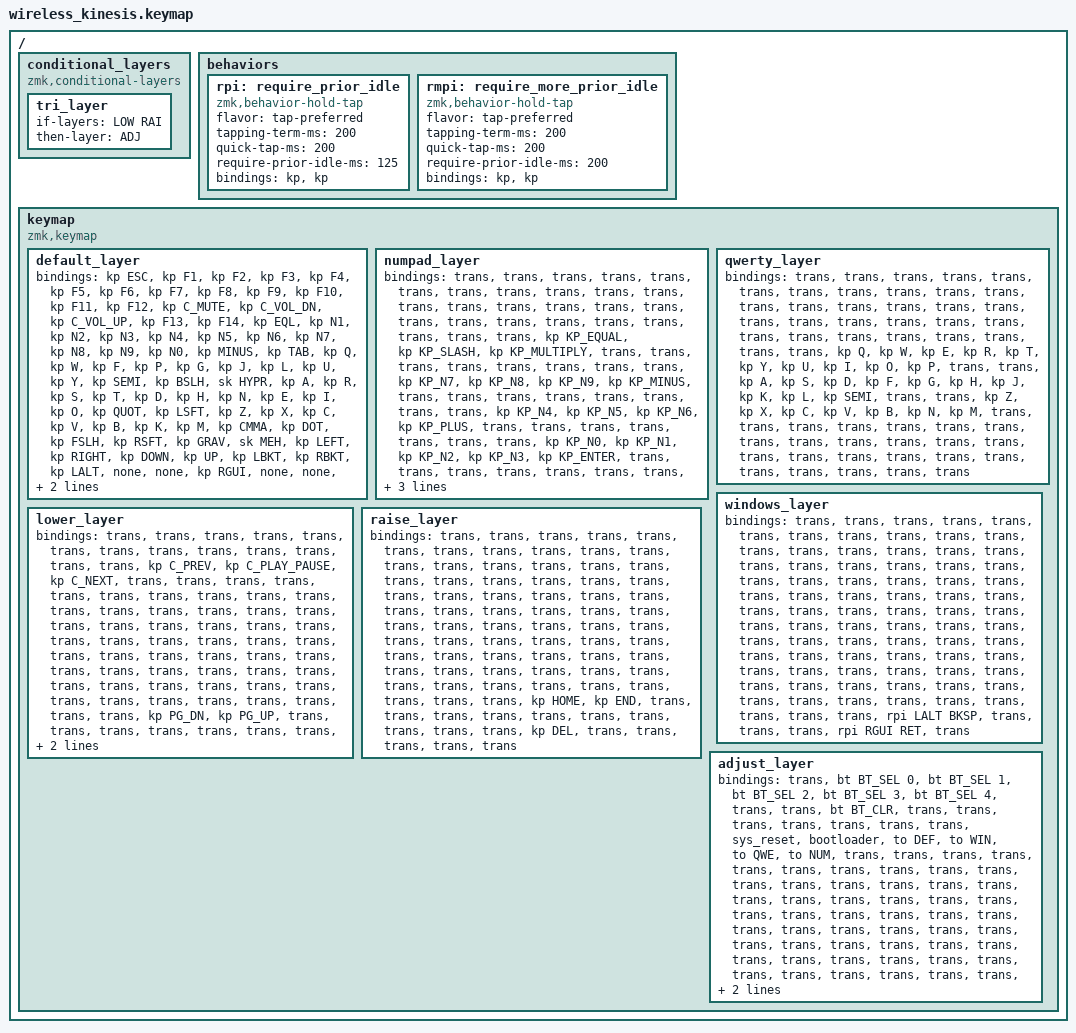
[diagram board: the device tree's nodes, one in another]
#include <behaviors.dtsi>
#include <dt-bindings/zmk/keys.h>
#include <dt-bindings/zmk/bt.h>

// Layers defines
#define DEF   0
#define NUM   1
#define QWE   2
#define WIN   3
#define LOW   4
#define RAI   5
#define ADJ   6

#define HYPR LS(LC(LA(LGUI)))
#define MEH  LS(LC(LALT))

/ {
    conditional_layers {
        compatible = "zmk,conditional-layers";
        tri_layer {
            if-layers = <LOW RAI>;
            then-layer = <ADJ>;
        };
    };

    behaviors {
        rpi: require_prior_idle {
            compatible = "zmk,behavior-hold-tap";
            #binding-cells = <2>;
            flavor = "tap-preferred";
            tapping-term-ms = <200>;
            quick-tap-ms = <200>;
            require-prior-idle-ms = <125>;
            bindings = <&kp>, <&kp>;
        };
        // This is only used for the `SPACE` mod-tap, I had some false positives on it.
        // Since space is fired pretty quickly during fast typing, increasing the `require_prior_idle`
        // value from `125` to `200` will make it less likely to trigger false positives.
        // See https://zmk.dev/docs/behaviors/hold-tap#advanced-configuration
        rmpi: require_more_prior_idle {
            compatible = "zmk,behavior-hold-tap";
            #binding-cells = <2>;
            flavor = "tap-preferred";
            tapping-term-ms = <200>;
            quick-tap-ms = <200>;
            require-prior-idle-ms = <200>;
            bindings = <&kp>, <&kp>;
        };
    };

    keymap {
        compatible = "zmk,keymap";

        default_layer { // 0
            bindings = <
&kp ESC   &kp F1 &kp F2 &kp F3 &kp F4 &kp F5 &kp F6 &kp F7 &kp F8                    &kp F9 &kp F10 &kp F11 &kp F12 &kp C_MUTE &kp C_VOL_DN &kp C_VOL_UP &kp F13 &kp F14

&kp EQL   &kp N1   &kp N2  &kp N3   &kp N4    &kp N5                                                  &kp N6  &kp N7   &kp N8   &kp N9   &kp N0   &kp MINUS
&kp TAB   &kp Q    &kp W   &kp F    &kp P     &kp G                                                   &kp J   &kp L    &kp U    &kp Y    &kp SEMI &kp BSLH
&sk HYPR  &kp A    &kp R   &kp S    &kp T     &kp D                                                   &kp H   &kp N    &kp E    &kp I    &kp O    &kp QUOT
&kp LSFT  &kp Z    &kp X   &kp C    &kp V     &kp B                                                   &kp K   &kp M    &kp CMMA &kp DOT  &kp FSLH &kp RSFT
          &kp GRAV &sk MEH &kp LEFT &kp RIGHT                                                                 &kp DOWN &kp UP   &kp LBKT &kp RBKT

                                                          &kp LALT &none              &none   &kp RGUI
                                                                   &none              &none
                                     &rpi LGUI BKSP  &mt LCTL ESC  &sl LOW            &sl RAI &rpi RALT RET &rmpi RCTL SPC
            >;
        };

        numpad_layer { // 1
            bindings = <
&trans    &trans &trans &trans &trans &trans &trans &trans &trans                    &trans &trans  &trans  &trans  &trans  &trans  &trans  &trans  &trans 

&trans    &trans   &trans  &trans   &trans    &trans                                                  &trans  &trans   &kp KP_EQUAL &kp KP_SLASH &kp KP_MULTIPLY    &trans 
&trans    &trans   &trans  &trans   &trans    &trans                                                  &trans  &kp KP_N7   &kp KP_N8    &kp KP_N9    &kp KP_MINUS  &trans  
&trans    &trans   &trans  &trans   &trans    &trans                                                  &trans  &kp KP_N4   &kp KP_N5    &kp KP_N6    &kp KP_PLUS  &trans  
&trans    &trans   &trans  &trans   &trans    &trans                                                  &kp KP_N0 &kp KP_N1   &kp KP_N2    &kp KP_N3    &kp KP_ENTER &trans  
          &trans   &trans  &trans   &trans                                                                    &trans   &trans    &kp KP_DOT   &kp KP_ENTER

                                                    &trans        &trans             &trans   &trans  
                                                                  &trans             &trans   
                                            &trans   &trans       &trans             &trans   &trans  &trans 
            >;
        };

        qwerty_layer { // 2
            bindings = <
&trans    &trans &trans &trans &trans &trans &trans &trans &trans                    &trans &trans  &trans  &trans  &trans  &trans  &trans  &trans  &trans 

&trans    &trans   &trans  &trans   &trans    &trans                                                  &trans  &trans   &trans   &trans   &trans   &trans 
&trans    &kp Q    &kp W   &kp E    &kp R     &kp T                                                   &kp Y   &kp U    &kp I    &kp O    &kp P    &trans  
&trans    &kp A    &kp S   &kp D    &kp F     &kp G                                                   &kp H   &kp J    &kp K    &kp L    &kp SEMI &trans  
&trans    &kp Z    &kp X   &kp C    &kp V     &kp B                                                   &kp N   &kp M    &trans   &trans   &trans   &trans  
          &trans   &trans  &trans   &trans                                                                    &trans   &trans   &trans   &trans  

                                                    &trans        &trans             &trans   &trans  
                                                                  &trans             &trans   
                                            &trans   &trans       &trans             &trans   &trans  &trans 
            >;
        };

        windows_layer { // 3
            bindings = <
&trans    &trans &trans &trans &trans &trans &trans &trans &trans                    &trans &trans  &trans  &trans  &trans  &trans  &trans  &trans  &trans 

&trans    &trans   &trans  &trans   &trans    &trans                                                  &trans  &trans   &trans   &trans   &trans   &trans 
&trans    &trans   &trans  &trans   &trans    &trans                                                  &trans  &trans   &trans   &trans   &trans   &trans  
&trans    &trans   &trans  &trans   &trans    &trans                                                  &trans  &trans   &trans   &trans   &trans   &trans  
&trans    &trans   &trans  &trans   &trans    &trans                                                  &trans  &trans   &trans   &trans   &trans   &trans  
          &trans   &trans  &trans   &trans                                                                    &trans   &trans   &trans   &trans  

                                                    &trans        &trans             &trans   &trans  
                                                                  &trans             &trans   
                                            &rpi LALT BKSP &trans       &trans             &trans   &rpi RGUI RET  &trans 
            >;
        };

        lower_layer { // 4
            bindings = <
&trans    &trans &trans &trans &trans &trans &trans &trans &trans                    &trans &trans &trans &trans &kp C_PREV &kp C_PLAY_PAUSE &kp C_NEXT &trans  &trans 

&trans    &trans   &trans  &trans   &trans    &trans                                                  &trans  &trans    &trans    &trans   &trans   &trans 
&trans    &trans   &trans  &trans   &trans    &trans                                                  &trans  &trans    &trans    &trans   &trans   &trans  
&trans    &trans   &trans  &trans   &trans    &trans                                                  &trans  &trans    &trans    &trans   &trans   &trans  
&trans    &trans   &trans  &trans   &trans    &trans                                                  &trans  &trans    &trans    &trans   &trans   &trans  
          &trans   &trans  &trans   &trans                                                                    &kp PG_DN &kp PG_UP &trans   &trans  

                                                    &trans        &trans             &trans   &trans  
                                                                  &trans             &trans   
                                            &trans   &trans       &trans             &trans   &trans  &trans 
    >;
        };

        raise_layer { // 5
            bindings = <
&trans    &trans &trans &trans &trans &trans &trans &trans &trans                    &trans &trans  &trans  &trans  &trans  &trans  &trans  &trans  &trans 

&trans    &trans   &trans  &trans   &trans    &trans                                                  &trans  &trans   &trans   &trans   &trans   &trans 
&trans    &trans   &trans  &trans   &trans    &trans                                                  &trans  &trans   &trans   &trans   &trans   &trans  
&trans    &trans   &trans  &trans   &trans    &trans                                                  &trans  &trans   &trans   &trans   &trans   &trans  
&trans    &trans   &trans  &trans   &trans    &trans                                                  &trans  &trans   &trans   &trans   &trans   &trans  
          &trans   &trans  &kp HOME &kp END                                                                   &trans   &trans   &trans   &trans  

                                                    &trans        &trans             &trans   &trans  
                                                                  &trans             &trans   
                                            &kp DEL  &trans       &trans             &trans   &trans  &trans 
            >;
        };

        adjust_layer { //6
            bindings = <
&trans     &bt BT_SEL 0 &bt BT_SEL 1 &bt BT_SEL 2 &bt BT_SEL 3 &bt BT_SEL 4 &trans &trans &bt BT_CLR                &trans &trans  &trans  &trans  &trans  &trans  &trans  &sys_reset  &bootloader

&to  DEF  &to  WIN &to  QWE &to  NUM &trans    &trans                                                                      &trans  &trans   &trans   &trans   &trans   &trans 
&trans    &trans   &trans   &trans   &trans    &trans                                                                      &trans  &trans   &trans   &trans   &trans   &trans  
&trans    &trans   &trans   &trans   &trans    &trans                                                                      &trans  &trans   &trans   &trans   &trans   &trans  
&trans    &trans   &trans   &trans   &trans    &trans                                                                      &trans  &trans   &trans   &trans   &trans   &trans  
          &trans   &trans   &trans   &trans                                                                                        &trans   &trans   &trans   &trans  

                                                     &trans        &trans                                 &trans   &trans  
                                                                   &trans                                 &trans   
                                             &trans   &trans       &trans                                 &trans   &trans  &trans 
            >;
        };

    };
};

/*
 * Template:
 ```c
&trans    &trans &trans &trans &trans &trans &trans &trans &trans                    &trans &trans  &trans  &trans  &trans  &trans  &trans  &trans  &trans 

&trans    &trans   &trans  &trans   &trans    &trans                                                  &trans  &trans   &trans   &trans   &trans   &trans 
&trans    &trans   &trans  &trans   &trans    &trans                                                  &trans  &trans   &trans   &trans   &trans   &trans  
&trans    &trans   &trans  &trans   &trans    &trans                                                  &trans  &trans   &trans   &trans   &trans   &trans  
&trans    &trans   &trans  &trans   &trans    &trans                                                  &trans  &trans   &trans   &trans   &trans   &trans  
          &trans   &trans  &trans   &trans                                                                    &trans   &trans   &trans   &trans  

                                                    &trans        &trans             &trans   &trans  
                                                                  &trans             &trans   
                                            &trans   &trans       &trans             &trans   &trans  &trans 
 ```

```markdown
# Useful links
- [keycodes](https://zmk.dev/docs/codes)
```
 */

// vim: set ft=c:
